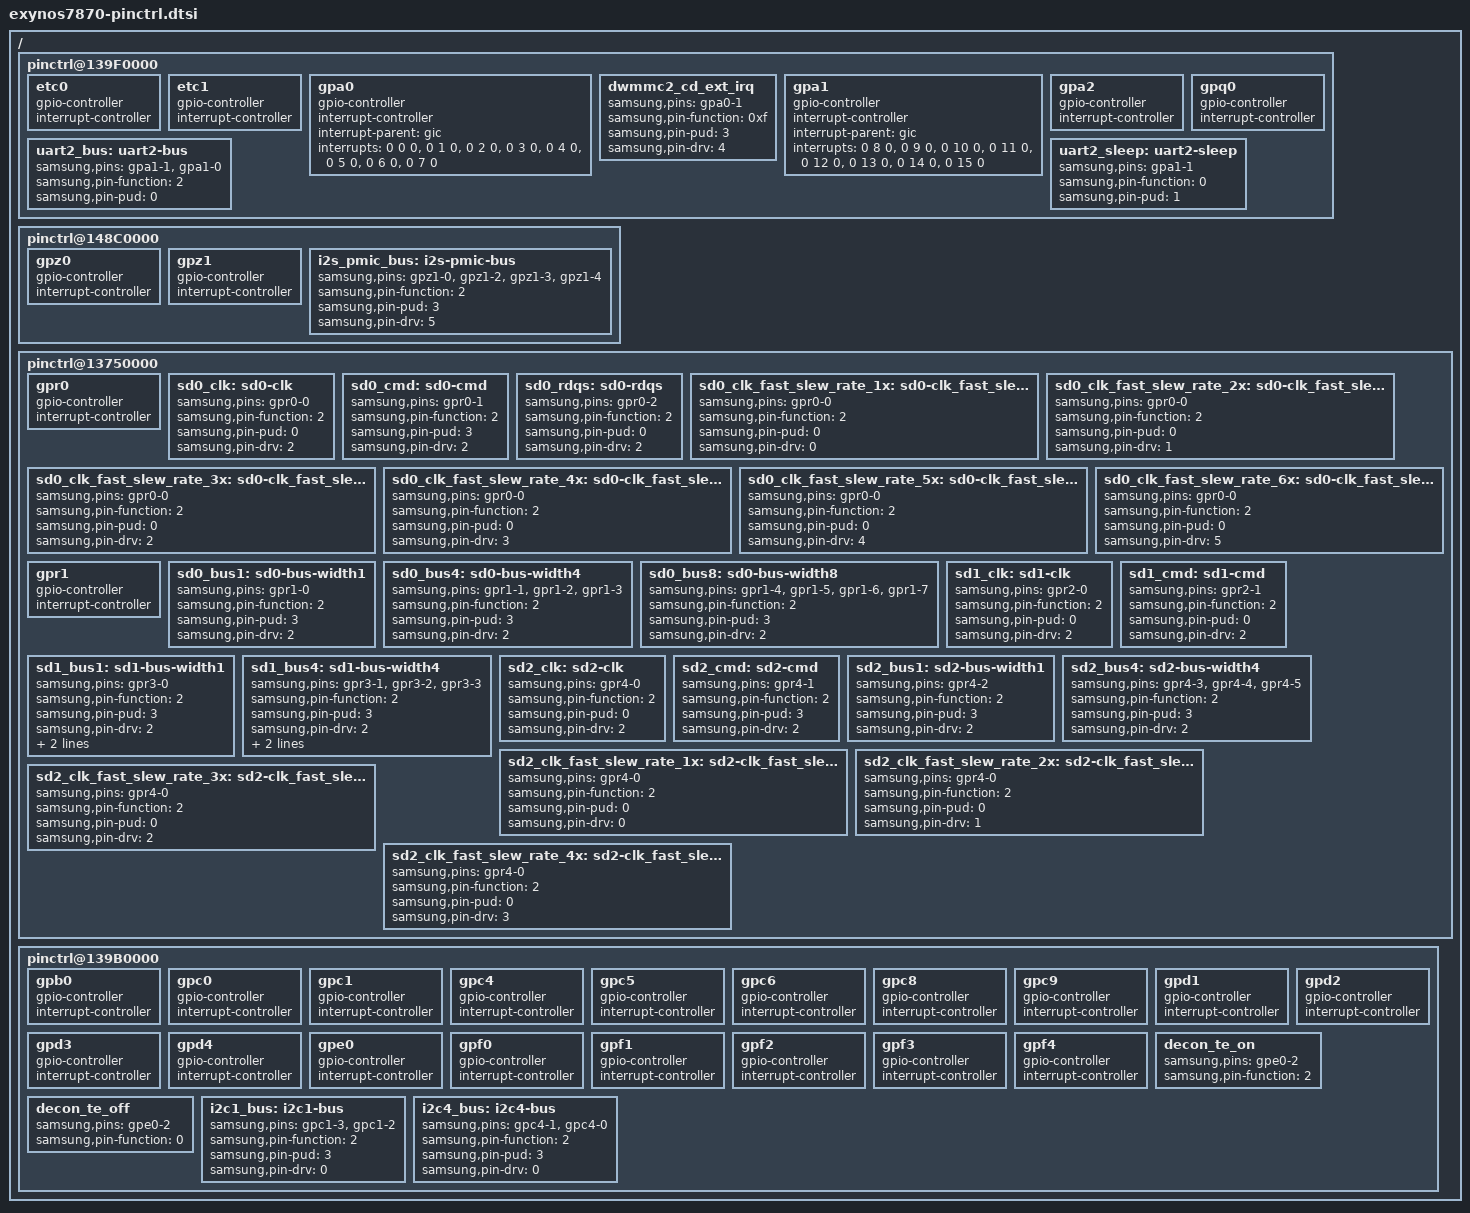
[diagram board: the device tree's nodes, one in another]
/*
 * Samsung's Exynos7870 SoC pin-mux and pin-config device tree source
 *
 * Copyright (c) 2014 Samsung Electronics Co., Ltd.
 *		http://www.samsung.com
 * Copyright (c) 2020 Dzmitry Sankouski (dsankouski@gmail.com)
 *
 * Samsung's Exynos7870 SoC pin-mux and pin-config options are listed as device
 * tree nodes are listed in this file.
 *
 * This program is free software; you can redistribute it and/or modify
 * it under the terms of the GNU General Public License version 2 as
 * published by the Free Software Foundation.
*/

/ {
	/* ALIVE */
	pinctrl@139F0000 {
		etc0: etc0 {
			gpio-controller;
			#gpio-cells = <2>;

			interrupt-controller;
			#interrupt-cells = <2>;
		};

		etc1: etc1 {
			gpio-controller;
			#gpio-cells = <2>;

			interrupt-controller;
			#interrupt-cells = <2>;
		};

		gpa0: gpa0 {
			gpio-controller;
			#gpio-cells = <2>;

			interrupt-controller;
			#interrupt-cells = <3>;
			interrupt-parent = <&gic>;
			interrupts = <0 0 0>, <0 1 0>, <0 2 0>, <0 3 0>,
				     <0 4 0>, <0 5 0>, <0 6 0>, <0 7 0>;
		};

		dwmmc2_cd_ext_irq: dwmmc2_cd_ext_irq {
			samsung,pins = "gpa0-1";
			samsung,pin-function = <0xf>;
			samsung,pin-pud = <3>;
			samsung,pin-drv = <4>;
		};

		gpa1: gpa1 {
			gpio-controller;
			#gpio-cells = <2>;

			interrupt-controller;
			#interrupt-cells = <3>;
			interrupt-parent = <&gic>;
			interrupts = <0 8 0>, <0 9 0>, <0 10 0>, <0 11 0>,
				     <0 12 0>, <0 13 0>, <0 14 0>, <0 15 0>;
		};

		gpa2: gpa2 {
			gpio-controller;
			#gpio-cells = <2>;

			interrupt-controller;
			#interrupt-cells = <2>;
		};

		gpq0: gpq0 {
			gpio-controller;
			#gpio-cells = <2>;

			interrupt-controller;
			#interrupt-cells = <2>;
		};

		/* UART_DEBUG */
		uart2_bus: uart2-bus {
			samsung,pins = "gpa1-1", "gpa1-0";
			samsung,pin-function = <2>;
			samsung,pin-pud = <0>;
		};

		uart2_sleep: uart2-sleep {
			samsung,pins = "gpa1-1";
			samsung,pin-function = <0>;
			samsung,pin-pud = <1>;
		};
	};

	pinctrl@148C0000 {
		gpz0: gpz0 {
			gpio-controller;
			#gpio-cells = <2>;

			interrupt-controller;
			#interrupt-cells = <2>;
		};

		gpz1: gpz1 {
			gpio-controller;
			#gpio-cells = <2>;

			interrupt-controller;
			#interrupt-cells = <2>;
		};

		i2s_pmic_bus: i2s-pmic-bus {
			samsung,pins = "gpz1-0", "gpz1-2", "gpz1-3", "gpz1-4";
			samsung,pin-function = <2>;
			samsung,pin-pud = <3>;
			samsung,pin-drv = <5>;
		};
	};

    /* FSYS */
	pinctrl@13750000 {
		gpr0: gpr0 {
			gpio-controller;
			#gpio-cells = <2>;

			interrupt-controller;
			#interrupt-cells = <2>;
		};

		sd0_clk: sd0-clk {
			samsung,pins = "gpr0-0";
			samsung,pin-function = <2>;
			samsung,pin-pud = <0>;
			samsung,pin-drv = <2>;
		};

		sd0_cmd: sd0-cmd {
			samsung,pins = "gpr0-1";
			samsung,pin-function = <2>;
			samsung,pin-pud = <3>;
			samsung,pin-drv = <2>;
		};

		sd0_rdqs: sd0-rdqs {
			samsung,pins = "gpr0-2";
			samsung,pin-function = <2>;
			samsung,pin-pud = <0>;
			samsung,pin-drv = <2>;
		};

		sd0_clk_fast_slew_rate_1x: sd0-clk_fast_slew_rate_1x {
			samsung,pins = "gpr0-0";
			samsung,pin-function = <2>;
			samsung,pin-pud = <0>;
			samsung,pin-drv = <0>;
		};

		sd0_clk_fast_slew_rate_2x: sd0-clk_fast_slew_rate_2x {
			samsung,pins = "gpr0-0";
			samsung,pin-function = <2>;
			samsung,pin-pud = <0>;
			samsung,pin-drv = <1>;
		};

		sd0_clk_fast_slew_rate_3x: sd0-clk_fast_slew_rate_3x {
			samsung,pins = "gpr0-0";
			samsung,pin-function = <2>;
			samsung,pin-pud = <0>;
			samsung,pin-drv = <2>;
		};

		sd0_clk_fast_slew_rate_4x: sd0-clk_fast_slew_rate_4x {
			samsung,pins = "gpr0-0";
			samsung,pin-function = <2>;
			samsung,pin-pud = <0>;
			samsung,pin-drv = <3>;
		};

		sd0_clk_fast_slew_rate_5x: sd0-clk_fast_slew_rate_5x {
			samsung,pins = "gpr0-0";
			samsung,pin-function = <2>;
			samsung,pin-pud = <0>;
			samsung,pin-drv = <4>;
		};

		sd0_clk_fast_slew_rate_6x: sd0-clk_fast_slew_rate_6x {
			samsung,pins = "gpr0-0";
			samsung,pin-function = <2>;
			samsung,pin-pud = <0>;
			samsung,pin-drv = <5>;
		};

		gpr1: gpr1 {
			gpio-controller;
			#gpio-cells = <2>;

			interrupt-controller;
			#interrupt-cells = <2>;
		};

		sd0_bus1: sd0-bus-width1 {
			samsung,pins = "gpr1-0";
			samsung,pin-function = <2>;
			samsung,pin-pud = <3>;
			samsung,pin-drv = <2>;
		};

		sd0_bus4: sd0-bus-width4 {
			samsung,pins = "gpr1-1", "gpr1-2", "gpr1-3";
			samsung,pin-function = <2>;
			samsung,pin-pud = <3>;
			samsung,pin-drv = <2>;
		};

		sd0_bus8: sd0-bus-width8 {
			samsung,pins = "gpr1-4", "gpr1-5", "gpr1-6", "gpr1-7";
			samsung,pin-function = <2>;
			samsung,pin-pud = <3>;
			samsung,pin-drv = <2>;
		};

		sd1_clk: sd1-clk {
			samsung,pins = "gpr2-0";
			samsung,pin-function = <2>;
			samsung,pin-pud = <0>;
			samsung,pin-drv = <2>;
		};

		sd1_cmd: sd1-cmd {
			samsung,pins = "gpr2-1";
			samsung,pin-function = <2>;
			samsung,pin-pud = <0>;
			samsung,pin-drv = <2>;
		};

		sd1_bus1: sd1-bus-width1 {
			samsung,pins = "gpr3-0";
			samsung,pin-function = <2>;
			samsung,pin-pud = <3>;
			samsung,pin-drv = <2>;
			samsung,pin-con-pdn = <2>;
			samsung,pin-pud-pdn = <3>;
		};

		sd1_bus4: sd1-bus-width4 {
			samsung,pins = "gpr3-1", "gpr3-2", "gpr3-3";
			samsung,pin-function = <2>;
			samsung,pin-pud = <3>;
			samsung,pin-drv = <2>;
			samsung,pin-con-pdn = <2>;
			samsung,pin-pud-pdn = <3>;
		};

		sd2_clk: sd2-clk {
			samsung,pins = "gpr4-0";
			samsung,pin-function = <2>;
			samsung,pin-pud = <0>;
			samsung,pin-drv = <2>;
		};

		sd2_cmd: sd2-cmd {
			samsung,pins = "gpr4-1";
			samsung,pin-function = <2>;
			samsung,pin-pud = <3>;
			samsung,pin-drv = <2>;
		};

		sd2_bus1: sd2-bus-width1 {
			samsung,pins = "gpr4-2";
			samsung,pin-function = <2>;
			samsung,pin-pud = <3>;
			samsung,pin-drv = <2>;
		};

		sd2_bus4: sd2-bus-width4 {
			samsung,pins = "gpr4-3", "gpr4-4", "gpr4-5";
			samsung,pin-function = <2>;
			samsung,pin-pud = <3>;
			samsung,pin-drv = <2>;
		};

		sd2_clk_fast_slew_rate_1x: sd2-clk_fast_slew_rate_1x {
			samsung,pins = "gpr4-0";
			samsung,pin-function = <2>;
			samsung,pin-pud = <0>;
			samsung,pin-drv = <0>;
		};

		sd2_clk_fast_slew_rate_2x: sd2-clk_fast_slew_rate_2x {
			samsung,pins = "gpr4-0";
			samsung,pin-function = <2>;
			samsung,pin-pud = <0>;
			samsung,pin-drv = <1>;
		};

		sd2_clk_fast_slew_rate_3x: sd2-clk_fast_slew_rate_3x {
			samsung,pins = "gpr4-0";
			samsung,pin-function = <2>;
			samsung,pin-pud = <0>;
			samsung,pin-drv = <2>;
		};

		sd2_clk_fast_slew_rate_4x: sd2-clk_fast_slew_rate_4x {
			samsung,pins = "gpr4-0";
			samsung,pin-function = <2>;
			samsung,pin-pud = <0>;
			samsung,pin-drv = <3>;
		};
	};

    /* TOP */
	pinctrl@139B0000 {
		gpb0: gpb0 {
			gpio-controller;
			#gpio-cells = <2>;

			interrupt-controller;
			#interrupt-cells = <2>;
		};

		gpc0: gpc0 {
			gpio-controller;
			#gpio-cells = <2>;

			interrupt-controller;
			#interrupt-cells = <2>;
		};

		gpc1: gpc1 {
			gpio-controller;
			#gpio-cells = <2>;

			interrupt-controller;
			#interrupt-cells = <2>;
		};

		gpc4: gpc4 {
			gpio-controller;
			#gpio-cells = <2>;

			interrupt-controller;
			#interrupt-cells = <2>;
		};

		gpc5: gpc5 {
			gpio-controller;
			#gpio-cells = <2>;

			interrupt-controller;
			#interrupt-cells = <2>;
		};

		gpc6: gpc6 {
			gpio-controller;
			#gpio-cells = <2>;

			interrupt-controller;
			#interrupt-cells = <2>;
		};

		gpc8: gpc8 {
			gpio-controller;
			#gpio-cells = <2>;

			interrupt-controller;
			#interrupt-cells = <2>;
		};

		gpc9: gpc9 {
			gpio-controller;
			#gpio-cells = <2>;

			interrupt-controller;
			#interrupt-cells = <2>;
		};

		gpd1: gpd1 {
			gpio-controller;
			#gpio-cells = <2>;

			interrupt-controller;
			#interrupt-cells = <2>;
		};

		gpd2: gpd2 {
			gpio-controller;
			#gpio-cells = <2>;

			interrupt-controller;
			#interrupt-cells = <2>;
		};

		gpd3: gpd3 {
			gpio-controller;
			#gpio-cells = <2>;

			interrupt-controller;
			#interrupt-cells = <2>;
		};

		gpd4: gpd4 {
			gpio-controller;
			#gpio-cells = <2>;

			interrupt-controller;
			#interrupt-cells = <2>;
		};

		gpe0: gpe0 {
			gpio-controller;
			#gpio-cells = <2>;

			interrupt-controller;
			#interrupt-cells = <2>;
		};

		gpf0: gpf0 {
			gpio-controller;
			#gpio-cells = <2>;

			interrupt-controller;
			#interrupt-cells = <2>;
		};

		gpf1: gpf1 {
			gpio-controller;
			#gpio-cells = <2>;

			interrupt-controller;
			#interrupt-cells = <2>;
		};

		gpf2: gpf2 {
			gpio-controller;
			#gpio-cells = <2>;

			interrupt-controller;
			#interrupt-cells = <2>;
		};

		gpf3: gpf3 {
			gpio-controller;
			#gpio-cells = <2>;

			interrupt-controller;
			#interrupt-cells = <2>;
		};

		gpf4: gpf4 {
			gpio-controller;
			#gpio-cells = <2>;

			interrupt-controller;
			#interrupt-cells = <2>;
		};

		/* TE SIGNAL */
		decon_te_on: decon_te_on {
			samsung,pins = "gpe0-2";
			samsung,pin-function = <2>;
		};

		decon_te_off: decon_te_off {
			samsung,pins = "gpe0-2";
			samsung,pin-function = <0>;
		};

		/* I2C_MUIC */
		i2c1_bus: i2c1-bus {
			samsung,pins = "gpc1-3", "gpc1-2";
			samsung,pin-function = <2>;
			samsung,pin-pud = <3>;
			samsung,pin-drv = <0>;
		};

		/* I2C_FUELGAUGE */
		i2c4_bus: i2c4-bus {
			samsung,pins = "gpc4-1", "gpc4-0";
			samsung,pin-function = <2>;
			samsung,pin-pud = <3>;
			samsung,pin-drv = <0>;
		};
	};
};
